# CY8C5568AXI_060 register map
File version: 0.1
CY8C55
Registers are 8-bit, read-write, no defined reset value unless marked. A register's access mark holds for its fields unless they carry their own. Offsets are from the block's base; lines under a group give offsets from that group; [hi:lo] are bit positions; {n}, {i} and the like mark numbered series; 'fields as' and 'values as' point back to an identical list; <NAME> marks a mode.

## Memory map
0x400043A5 USBUART_Central size 0x1CF9 — USBFS
0x40006405 PrISM_8 size 0x41 — PrISM
0x40006406 PrISM_10 size 0x41 — PrISM
0x40006409 PrISM_1 size 0x41 — PrISM
0x4000640A PrISM_5 size 0x41 — PrISM
0x4000640B PrISM_4 size 0x41 — PrISM
0x4000640C PrISM_2 size 0x41 — PrISM
0x4000640D PrISM_7 size 0x41 — PrISM
0x4000640E PrISM_3 size 0x41 — PrISM
0x4000640F PrISM_6 size 0x41 — PrISM
0x40006428 UART_Sensor size 0x40 — UART
0x4000646A UART_Debug size 0xFF — UART
0x40006504 PrISM_13 size 0x41 — PrISM
0x40006505 PrISM_12 size 0x41 — PrISM
0x40006506 PrISM_11 size 0x41 — PrISM
0x40006507 PrISM_9 size 0x41 — PrISM
0x40006508 PrISM_14 size 0x41 — PrISM

## PrISM_11 — PrISM
Base 0x40006506
Same registers: PrISM_8 0x40006405, PrISM_10 0x40006406, PrISM_1 0x40006409, PrISM_5 0x4000640A, PrISM_4 0x4000640B, PrISM_2 0x4000640C, PrISM_7 0x4000640D, PrISM_3 0x4000640E, PrISM_6 0x4000640F, PrISM_13 0x40006504, PrISM_12 0x40006505, PrISM_9 0x40006507, PrISM_14 0x40006508
0x00 PrISM_SEED — Current seed value
0x10 PrISM_POLYNOM — Polynomial
0x20 PrISM_DENSITY0 — Pulse Density 0
0x30 PrISM_DENSITY1 — Pulse Density 1
0x40 PrISM_SEED_COPY — Start seed value

## UART_Sensor — UART
Base 0x40006428
0x00 RX_UART_Sensor_RX_ADDRESS1 — RX Address1 Register
0x10 RX_UART_Sensor_RX_ADDRESS2 — RX Address2 Register
0x1C TX_UART_Sensor_TX_DATA — TX Data Register
0x20 RX_UART_Sensor_RX_DATA — RX Data Register
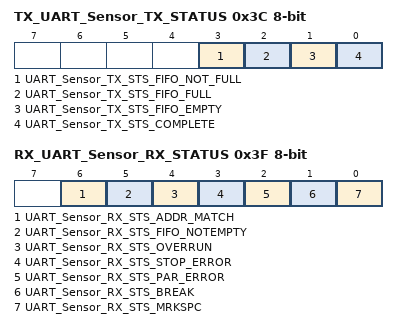
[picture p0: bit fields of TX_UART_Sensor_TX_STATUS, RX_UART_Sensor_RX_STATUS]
0x3C TX_UART_Sensor_TX_STATUS — TX status register
  [3] UART_Sensor_TX_STS_FIFO_NOT_FULL ro, [2] UART_Sensor_TX_STS_FIFO_FULL ro, [1] UART_Sensor_TX_STS_FIFO_EMPTY ro, [0] UART_Sensor_TX_STS_COMPLETE ro
0x3F RX_UART_Sensor_RX_STATUS — RX status register
  [6] UART_Sensor_RX_STS_ADDR_MATCH ro, [5] UART_Sensor_RX_STS_FIFO_NOTEMPTY ro, [4] UART_Sensor_RX_STS_OVERRUN ro, [3] UART_Sensor_RX_STS_STOP_ERROR ro, [2] UART_Sensor_RX_STS_PAR_ERROR ro, [1] UART_Sensor_RX_STS_BREAK ro, [0] UART_Sensor_RX_STS_MRKSPC ro

## UART_Debug — UART
Base 0x4000646A
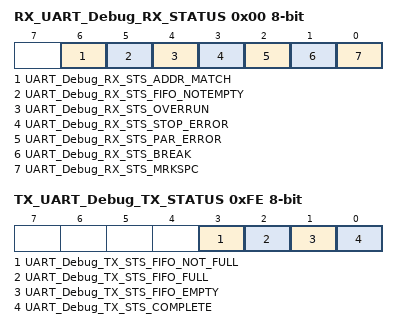
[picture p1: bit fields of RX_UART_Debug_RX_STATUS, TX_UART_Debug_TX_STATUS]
0x00 RX_UART_Debug_RX_STATUS — RX status register
  [6] UART_Debug_RX_STS_ADDR_MATCH ro, [5] UART_Debug_RX_STS_FIFO_NOTEMPTY ro, [4] UART_Debug_RX_STS_OVERRUN ro, [3] UART_Debug_RX_STS_STOP_ERROR ro, [2] UART_Debug_RX_STS_PAR_ERROR ro, [1] UART_Debug_RX_STS_BREAK ro, [0] UART_Debug_RX_STS_MRKSPC ro
0xC0 RX_UART_Debug_RX_ADDRESS1 — RX Address1 Register
0xD0 RX_UART_Debug_RX_ADDRESS2 — RX Address2 Register
0xE0 RX_UART_Debug_RX_DATA — RX Data Register
0xE1 TX_UART_Debug_TX_DATA — TX Data Register
0xFE TX_UART_Debug_TX_STATUS — TX status register
  [3] UART_Debug_TX_STS_FIFO_NOT_FULL ro, [2] UART_Debug_TX_STS_FIFO_FULL ro, [1] UART_Debug_TX_STS_FIFO_EMPTY ro, [0] UART_Debug_TX_STS_COMPLETE ro

## USBUART_Central — USBFS
Base 0x400043A5
0x00 USBUART_Central_PM_ACT_CFG — Active Power Mode Configuration Register
0x10 USBUART_Central_PM_STBY_CFG — Standby Power Mode Configuration Register
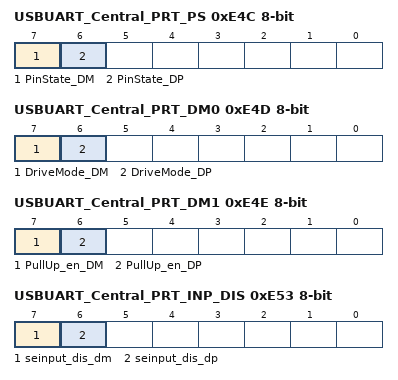
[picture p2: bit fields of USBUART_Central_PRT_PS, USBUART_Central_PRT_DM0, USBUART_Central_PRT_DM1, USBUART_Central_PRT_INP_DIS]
0xE4C USBUART_Central_PRT_PS — Port Pin State Register
  [7] PinState_DM ro, [6] PinState_DP ro
0xE4D USBUART_Central_PRT_DM0 — Port Drive Mode Register
  [7] DriveMode_DM, [6] DriveMode_DP
0xE4E USBUART_Central_PRT_DM1 — Port Drive Mode Register
  [7] PullUp_en_DM, [6] PullUp_en_DP
0xE53 USBUART_Central_PRT_INP_DIS — Input buffer disable override
  [7] seinput_dis_dm, [6] seinput_dis_dp
0x1C5B USBUART_Central_EP0_DR0 — bmRequestType
0x1C5C USBUART_Central_EP0_DR1 — bRequest
0x1C5D USBUART_Central_EP0_DR2 — wValueLo
0x1C5E USBUART_Central_EP0_DR3 — wValueHi
0x1C5F USBUART_Central_EP0_DR4 — wIndexLo
0x1C60 USBUART_Central_EP0_DR5 — wIndexHi
0x1C61 USBUART_Central_EP0_DR6 — lengthLo
0x1C62 USBUART_Central_EP0_DR7 — lengthHi
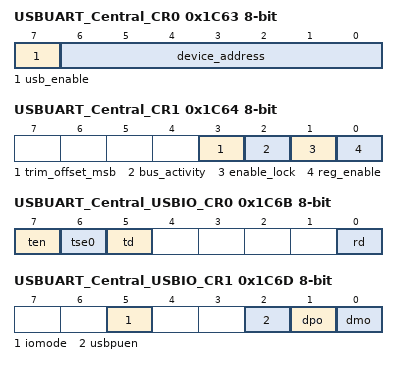
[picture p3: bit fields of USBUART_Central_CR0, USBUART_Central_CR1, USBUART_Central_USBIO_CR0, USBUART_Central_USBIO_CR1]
0x1C63 USBUART_Central_CR0 — USB Control Register 0
  [7] usb_enable, [6:0] device_address ro
0x1C64 USBUART_Central_CR1 — USB Control Register 1
  [3] trim_offset_msb, [2] bus_activity, [1] enable_lock, [0] reg_enable
{0x1C59+0x10*i} USBUART_Central_SIE_EP{i}_CR0 (i=1..8) — The Endpoint{i} Control Register
0x1C6B USBUART_Central_USBIO_CR0 — USBIO Control Register 0
  [7] ten, [6] tse0, [5] td, [0] rd ro
0x1C6D USBUART_Central_USBIO_CR1 — USBIO Control Register 1
  [5] iomode, [2] usbpuen, [1] dpo ro, [0] dmo ro
0x1CE7 USBUART_Central_BUF_SIZE — Dedicated Endpoint Buffer Size Register
0x1CE9 USBUART_Central_EP_ACTIVE — Endpoint Active Indication Register
0x1CEA USBUART_Central_EP_TYPE — Endpoint Type (IN/OUT) Indication
0x1CF8 USBUART_Central_USB_CLK_EN — USB Block Clock Enable Register
